# CEC1712H_N2_SX register map
Vendor: Microchip Technology; Series: CEC1712H_N2_SX; File version: 0
CPU: CM4 r1p0, little endian, no MPU, 3 interrupt priority bits, 172 interrupts
Registers are 32-bit, read-write, reset 0x0 unless marked. A register's access mark holds for its fields unless they carry their own. Offsets are from the block's base; [hi:lo] are bit positions.

## WEEK — The Week Timer and the Sub-Week Timer assert the Power-Up Event Output which automatically powers-up the system from the G3 state
Base 0x4000AC80; register names take the prefix WEEK_
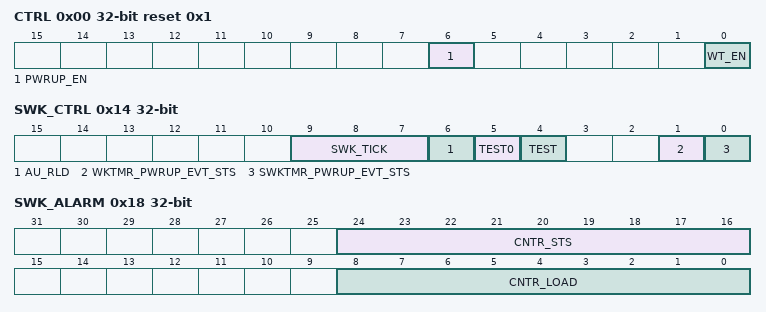
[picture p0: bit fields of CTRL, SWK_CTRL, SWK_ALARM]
0x00 CTRL reset 0x1 — Control Register
  [6] PWRUP_EN — This bit controls the state of the Power-Up Event Output and enables Week POWER-UP Event decoding in the VBAT-Powered Control Interface. 1=Power-Up Event Output Enabled. 0=Power-Up Event Output Disabled and Reset
  [0] WT_EN — The WT_ENABLE bit is used to start and stop the Week Alarm Counter Register and the Clock Divider Register. The value in the Counter Register is held when the WT_ENABLE bit is not asserted (0) and the count is resumed from the last value when the bit is asserted (1). The 15-Bit Clock Divider is reset to 00h and the Week Alarm Interface is in its lowest power consumption state when the WT_ENABLE bit is not asserted.
0x04 ALARM_CNT — Week Alarm Counter Register
  [27:0] WK_CNTR — While the WT_ENABLE bit is 1, this register is incremented at a 1 Hz rate. Writes of this register may require one second to take effect. Reads return the current state of the register. Reads and writes complete independently of the state of WT_ENABLE.
0x08 TMR_COMP reset 0xFFFFFFF — Week Timer Compare Register
  [27:0] WK_COMP — A Week Alarm Interrupt and a Week Alarm Power-Up Event are asserted when the Week Alarm Counter Register is greater than or equal to the contents of this register. Reads and writes complete independently of the state of WT_ENABLE.
0x0C CLKDIV — Clock Divider Register
  [14:0] DIV — Reads of this register return the current state of the Week Timer 15- bit clock divider.
0x10 SS_INTR_SEL — Sub-Second Programmable Interrupt Select Register
  [3:0] SPISR — This field determines the rate at which Sub-Second interrupt events are generated.
0x14 SWK_CTRL ro — Sub-Week Control Register
  [9:7] SWK_TICK — This field selects the clock source for the Sub-Week Counter.
  [6] AU_RLD — 1= No reload occurs when the Sub-Week Counter expires. 0= Reloads the SUBWEEK_COUNTER_LOAD field into the Sub- Week Counter when the counter expires.
  [5] TEST0 — Test
  [4] TEST
  [1] WKTMR_PWRUP_EVT_STS — This bit is set to 1 when the Week Alarm Counter Register is greater than or equal the contents of the Week Timer Compare. Register and the POWERUP_EN is 1. Writes of 1 clear this bit. Writes of 0 have no effect. Note: This bit does not have to be cleared to remove a Week Timer Power-Up Event.
  [0] SWKTMR_PWRUP_EVT_STS — This bit is set to 1 when the Sub-Week Alarm Counter Register decrements from 1 to 0 and the POWERUP_EN is 1. Writes of 1 clear this bit. Writes of 0 have no effect. Note: This bit MUST be cleared to remove a Sub-Week Timer Power-Up Event.
0x18 SWK_ALARM ro — Sub-Week Alarm Counter Register
  [24:16] CNTR_STS — Reads of this register return the current state of the 9-bit Sub-Week Alarm counter.
  [8:0] CNTR_LOAD — Writes with a non-zero value to this field reload the 9-bit Sub-Week Alarm counter. Writes of 0 disable the counter. If the Sub-Week Alarm counter decrements to 0 and the AUTO_RELOAD bit is set, the value in this field is automatically loaded into the Sub-Week Alarm counter.

## PWM0 — The PWM block generates an arbitrary duty cycle output at frequencies from less than 0.1 Hz to 24 MHz
Base 0x40005800; register names take the prefix PWM_
Same registers: PWM2 0x40005820, PWM3 0x40005830, PWM5 0x40005850, PWM6 0x40005860, PWM7 0x40005870
0x00 CNT_ON — This field determines both the frequency and duty cycle of the PWM signal. Setting this field to a value of n will cause the On time of the PWM to be n+1 cycles of the PWM Clock Source. When this field is set to zero and the PWMX_COUNTER_OFF_TIME is not set to zero, the PWM_OUTPUT is held low (Full Off).
0x04 CNT_OFF reset 0xFFFF — This field determine both the frequency and duty cycle of the PWM signal. Setting this field to a value of n will cause the Off time of the PWM to be n+1 cycles of the PWM Clock Source. When this field is set to zero, the PWM_OUTPUT is held high (Full On).
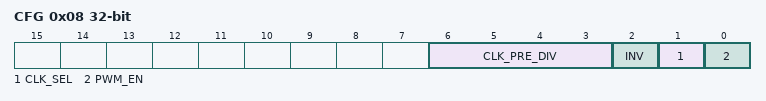
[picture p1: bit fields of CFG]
0x08 CFG — PWMx CONFIGURATION REGISTER
  [6:3] CLK_PRE_DIV — The Clock source for the 16-bit down counter (see PWMx Counter ON Time Register and PWMx Counter OFF Time Register) is determined by bit D1 of this register. The Clock source is then divided by the value of Pre-Divider+1 and the resulting signal determines the rate at which the down counter will be decremented. For example, a Pre-Divider value of 1 divides the input clock by 2 and a value of 2 divides the input clock by 3. A Pre-Divider of 0 will disable the Pre-Divider option.
  [2] INV — 1= PWM_OUTPUT ON State is active low; 0=PWM_OUTPUT ON State is active high.
  [1] CLK_SEL — This bit determines the clock source used by the PWM duty cycle and frequency control logic. 1=CLOCK_LOW. 0=CLOCK_HIGH
  [0] PWM_EN — When the PWM_ENABLE is set to 0 the internal counters are reset and the internal state machine is set to the OFF state. In addition, the PWM_OUTPUT signal is set to the inactive state as determined by the Invert bit. The PWMx Counter ON Time Register and PWMx Counter OFF Time Register are not affected by the PWM_ENABLE bit and may be read and written while the PWM enable bit is 0. 1=Enabled (default); 0=Disabled (gates clocks to save power).
